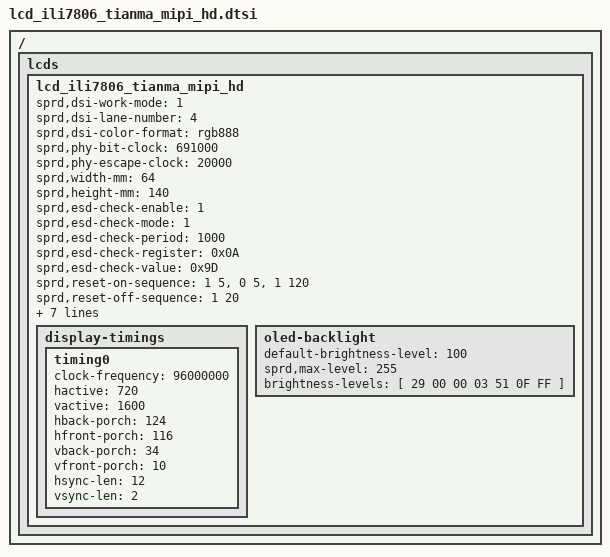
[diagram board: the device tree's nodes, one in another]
/ { lcds {
	lcd_ili7806_tianma_mipi_hd: lcd_ili7806_tianma_mipi_hd {

		sprd,dsi-work-mode = <1>;
		sprd,dsi-lane-number = <4>;
		sprd,dsi-color-format = "rgb888";

		sprd,phy-bit-clock = <691000>;
		sprd,phy-escape-clock = <20000>;

		sprd,width-mm = <64>;
		sprd,height-mm = <140>;

		sprd,esd-check-enable = <1>;
		sprd,esd-check-mode = <1>;
		sprd,esd-check-period = <1000>;
		sprd,esd-check-register = <0x0A>;
		sprd,esd-check-value = <0x9D>;

		sprd,reset-on-sequence = <1 5>, <0 5>, <1 120>;
		sprd,reset-off-sequence = <1 20>;
		sprd,bias-cmd-sequence =  <0x0 0x14>, <0x1 0x14>;
		sprd,initial-command = [
			39 00 00 04 FF 78 07 00
			13 48 00 01 11
			39 00 00 04 FF 78 07 03
			23 00 00 02 C6 16
			23 00 00 02 80 04
			23 00 00 02 81 04
			23 00 00 02 82 04
			23 00 00 02 83 E0
			23 00 00 02 84 00
		//	39 00 00 04 FF 78 07 06
		//	23 00 00 02 3E E2
			39 00 00 04 FF 78 07 00
			39 00 00 03 51 00 00
			23 00 00 02 53 2C
			23 00 00 02 55 03
			39 00 00 03 68 04 00
			13 40 00 01 29
			23 00 00 02 35 00
			];
		sprd,sleep-in-command = [
			13 0A 00 01 28
			13 78 00 01 10
			];
		sprd,sleep-out-command = [
			13 78 00 01 11
			13 64 00 01 29
			];

		display-timings {
			timing0 {
				clock-frequency = <96000000>;
				hactive = <720>;
				vactive = <1600>;
				hback-porch = <124>;
				hfront-porch = <116>;
				vback-porch = <34>;
				vfront-porch = <10>;
				hsync-len = <12>;
				vsync-len = <2>;
			};
		};

oled-backlight{
	default-brightness-level = <100>;
	sprd,max-level = <255>;
	brightness-levels = [
		29 00 00 03 51 0F FF
	];
};
};

};};
